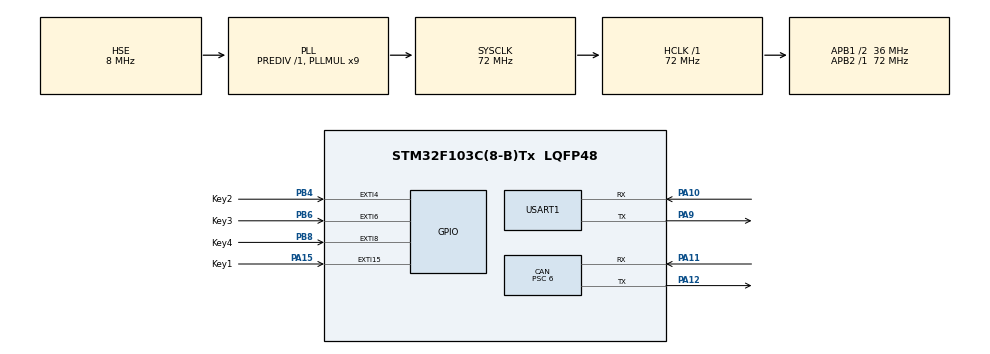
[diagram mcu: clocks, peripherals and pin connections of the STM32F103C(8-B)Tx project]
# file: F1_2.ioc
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CAN.ABOM=ENABLE
CAN.BS1=CAN_BS1_8TQ
CAN.BS2=CAN_BS2_3TQ
CAN.CalculateBaudRate=499999
CAN.CalculateTimeBit=2000
CAN.CalculateTimeQuantum=166.66666666666669
CAN.Prescaler=6
FREERTOS.Tasks01=CANTASK,0,256,Can_Task,Default,NULL,Dynamic,NULL,NULL
Mcu.Family=STM32F1
Mcu.Name=STM32F103C(8-B)Tx
Mcu.Package=LQFP48
NVIC.EXTI15_10_IRQn=true\:0\:0\:false\:false\:true\:false\:true\:true\:true
NVIC.EXTI4_IRQn=true\:0\:0\:false\:false\:true\:false\:true\:true\:true
NVIC.EXTI9_5_IRQn=true\:0\:0\:false\:false\:true\:false\:true\:true\:true
NVIC.PriorityGroup=NVIC_PRIORITYGROUP_4
PA10.Mode=Asynchronous
PA10.Signal=USART1_RX
PA11.Mode=CAN_Activate
PA11.Signal=CAN_RX
PA12.Mode=CAN_Activate
PA12.Signal=CAN_TX
PA13.Mode=Serial_Wire
PA13.Signal=SYS_JTMS-SWDIO
PA14.Mode=Serial_Wire
PA14.Signal=SYS_JTCK-SWCLK
PA15.GPIO_Label=Key1
PA15.GPIO_ModeDefaultEXTI=GPIO_MODE_IT_FALLING
PA15.GPIO_PuPd=GPIO_PULLUP
PA15.Signal=GPXTI15
PA9.Mode=Asynchronous
PA9.Signal=USART1_TX
PB4.GPIO_Label=Key2
PB4.GPIO_ModeDefaultEXTI=GPIO_MODE_IT_FALLING
PB4.GPIO_PuPd=GPIO_PULLUP
PB4.Signal=GPXTI4
PB6.GPIO_Label=Key3
PB6.GPIO_ModeDefaultEXTI=GPIO_MODE_IT_FALLING
PB6.GPIO_PuPd=GPIO_PULLUP
PB6.Signal=GPXTI6
PB8.GPIO_Label=Key4
PB8.GPIO_ModeDefaultEXTI=GPIO_MODE_IT_FALLING
PB8.GPIO_PuPd=GPIO_PULLUP
PB8.Signal=GPXTI8
PC14-OSC32_IN.Mode=LSE-External-Oscillator
PC14-OSC32_IN.Signal=RCC_OSC32_IN
PC15-OSC32_OUT.Mode=LSE-External-Oscillator
PC15-OSC32_OUT.Signal=RCC_OSC32_OUT
PD0-OSC_IN.Mode=HSE-External-Oscillator
PD0-OSC_IN.Signal=RCC_OSC_IN
PD1-OSC_OUT.Mode=HSE-External-Oscillator
PD1-OSC_OUT.Signal=RCC_OSC_OUT
ProjectManager.HeapSize=0x200
ProjectManager.StackSize=0x400
ProjectManager.TargetToolchain=MDK-ARM V5.32
RCC.AHBFreq_Value=72000000
RCC.APB1CLKDivider=RCC_HCLK_DIV2
RCC.APB1Freq_Value=36000000
RCC.APB1TimFreq_Value=72000000
RCC.APB2Freq_Value=72000000
RCC.APB2TimFreq_Value=72000000
RCC.HCLKFreq_Value=72000000
RCC.PLLMUL=RCC_PLL_MUL9
RCC.PLLSourceVirtual=RCC_PLLSOURCE_HSE
RCC.SYSCLKFreq_VALUE=72000000
RCC.SYSCLKSource=RCC_SYSCLKSOURCE_PLLCLK
RCC.USBFreq_Value=72000000
USART1.VirtualMode=VM_ASYNC
VP_FREERTOS_VS_CMSIS_V1.Mode=CMSIS_V1
board=custom

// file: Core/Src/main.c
/* USER CODE BEGIN Header */
/**
  ******************************************************************************
  * @file           : main.c
  * @brief          : Main program body
  ******************************************************************************
  * @attention
  *
  * Copyright (c) 2026 STMicroelectronics.
  * All rights reserved.
  *
  * This software is licensed under terms that can be found in the LICENSE file
  * in the root directory of this software component.
  * If no LICENSE file comes with this software, it is provided AS-IS.
  *
  ******************************************************************************
  */
/* USER CODE END Header */
#include "main.h"
#include "cmsis_os.h"
#include "can.h"
#include "usart.h"
#include "gpio.h"

void SystemClock_Config(void);
void MX_FREERTOS_Init(void);

int main(void)
{

  /* MCU Configuration--------------------------------------------------------*/

  /* Reset of all peripherals, Initializes the Flash interface and the Systick. */
  HAL_Init();

  /* Configure the system clock */
  SystemClock_Config();

  /* Initialize all configured peripherals */
  MX_GPIO_Init();
  MX_CAN_Init();
  MX_USART1_UART_Init();

  /* Call init function for freertos objects (in cmsis_os2.c) */
  MX_FREERTOS_Init();

  /* Start scheduler */
  osKernelStart();

  /* We should never get here as control is now taken by the scheduler */

  /* Infinite loop */
  while (1)
  {

  }
}

void SystemClock_Config(void)
{
  RCC_OscInitTypeDef RCC_OscInitStruct = {0};
  RCC_ClkInitTypeDef RCC_ClkInitStruct = {0};

  /** Initializes the RCC Oscillators according to the specified parameters
  * in the RCC_OscInitTypeDef structure.
  */
  RCC_OscInitStruct.OscillatorType = RCC_OSCILLATORTYPE_HSE;
  RCC_OscInitStruct.HSEState = RCC_HSE_ON;
  RCC_OscInitStruct.HSEPredivValue = RCC_HSE_PREDIV_DIV1;
  RCC_OscInitStruct.HSIState = RCC_HSI_ON;
  RCC_OscInitStruct.PLL.PLLState = RCC_PLL_ON;
  RCC_OscInitStruct.PLL.PLLSource = RCC_PLLSOURCE_HSE;
  RCC_OscInitStruct.PLL.PLLMUL = RCC_PLL_MUL9;
  if (HAL_RCC_OscConfig(&RCC_OscInitStruct) != HAL_OK)
  {
    Error_Handler();
  }

  /** Initializes the CPU, AHB and APB buses clocks
  */
  RCC_ClkInitStruct.ClockType = RCC_CLOCKTYPE_HCLK|RCC_CLOCKTYPE_SYSCLK
                              |RCC_CLOCKTYPE_PCLK1|RCC_CLOCKTYPE_PCLK2;
  RCC_ClkInitStruct.SYSCLKSource = RCC_SYSCLKSOURCE_PLLCLK;
  RCC_ClkInitStruct.AHBCLKDivider = RCC_SYSCLK_DIV1;
  RCC_ClkInitStruct.APB1CLKDivider = RCC_HCLK_DIV2;
  RCC_ClkInitStruct.APB2CLKDivider = RCC_HCLK_DIV1;

  if (HAL_RCC_ClockConfig(&RCC_ClkInitStruct, FLASH_LATENCY_2) != HAL_OK)
  {
    Error_Handler();
  }
}

void Error_Handler(void)
{
  __disable_irq();
  while (1)
  {
  }
}

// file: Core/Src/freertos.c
/* USER CODE BEGIN Header */
/**
  ******************************************************************************
  * File Name          : freertos.c
  * Description        : Code for freertos applications
  ******************************************************************************
  * @attention
  *
  * Copyright (c) 2026 STMicroelectronics.
  * All rights reserved.
  *
  * This software is licensed under terms that can be found in the LICENSE file
  * in the root directory of this software component.
  * If no LICENSE file comes with this software, it is provided AS-IS.
  *
  ******************************************************************************
  */
/* USER CODE END Header */

#include "FreeRTOS.h"
#include "task.h"
#include "main.h"
#include "cmsis_os.h"

/* USER CODE BEGIN Includes */
#include "APP_can.h"
/* USER CODE END Includes */

osThreadId CANTASKHandle;

void Can_Task(void const * argument);

void MX_FREERTOS_Init(void); /* (MISRA C 2004 rule 8.1) */

/* GetIdleTaskMemory prototype (linked to static allocation support) */
void vApplicationGetIdleTaskMemory( StaticTask_t **ppxIdleTaskTCBBuffer, StackType_t **ppxIdleTaskStackBuffer, uint32_t *pulIdleTaskStackSize );

/* USER CODE BEGIN GET_IDLE_TASK_MEMORY */
static StaticTask_t xIdleTaskTCBBuffer;
static StackType_t xIdleStack[configMINIMAL_STACK_SIZE];

void vApplicationGetIdleTaskMemory( StaticTask_t **ppxIdleTaskTCBBuffer, StackType_t **ppxIdleTaskStackBuffer, uint32_t *pulIdleTaskStackSize )
{
  *ppxIdleTaskTCBBuffer = &xIdleTaskTCBBuffer;
  *ppxIdleTaskStackBuffer = &xIdleStack[0];
  *pulIdleTaskStackSize = configMINIMAL_STACK_SIZE;
  /* place for user code */
}
/* USER CODE END GET_IDLE_TASK_MEMORY */

void MX_FREERTOS_Init(void) {

  /* Create the thread(s) */
  /* definition and creation of CANTASK */
  osThreadDef(CANTASK, Can_Task, osPriorityNormal, 0, 256);
  CANTASKHandle = osThreadCreate(osThread(CANTASK), NULL);

}

void Can_Task(void const * argument)
{
  /* USER CODE BEGIN Can_Task */
  APP_CAN_Init(); /* start CAN; keys scanned in APP_can.c state machine */
  /* Infinite loop */
  for(;;)
  {
    APP_CAN_KeyScan(); /* poll keys with state-machine debounce */
#ifdef CAN_TEST_FLAG
    APP_CAN_Run(); /* loopback: poll RX + print */
#endif
    osDelay(1);
  }
  /* USER CODE END Can_Task */
}
